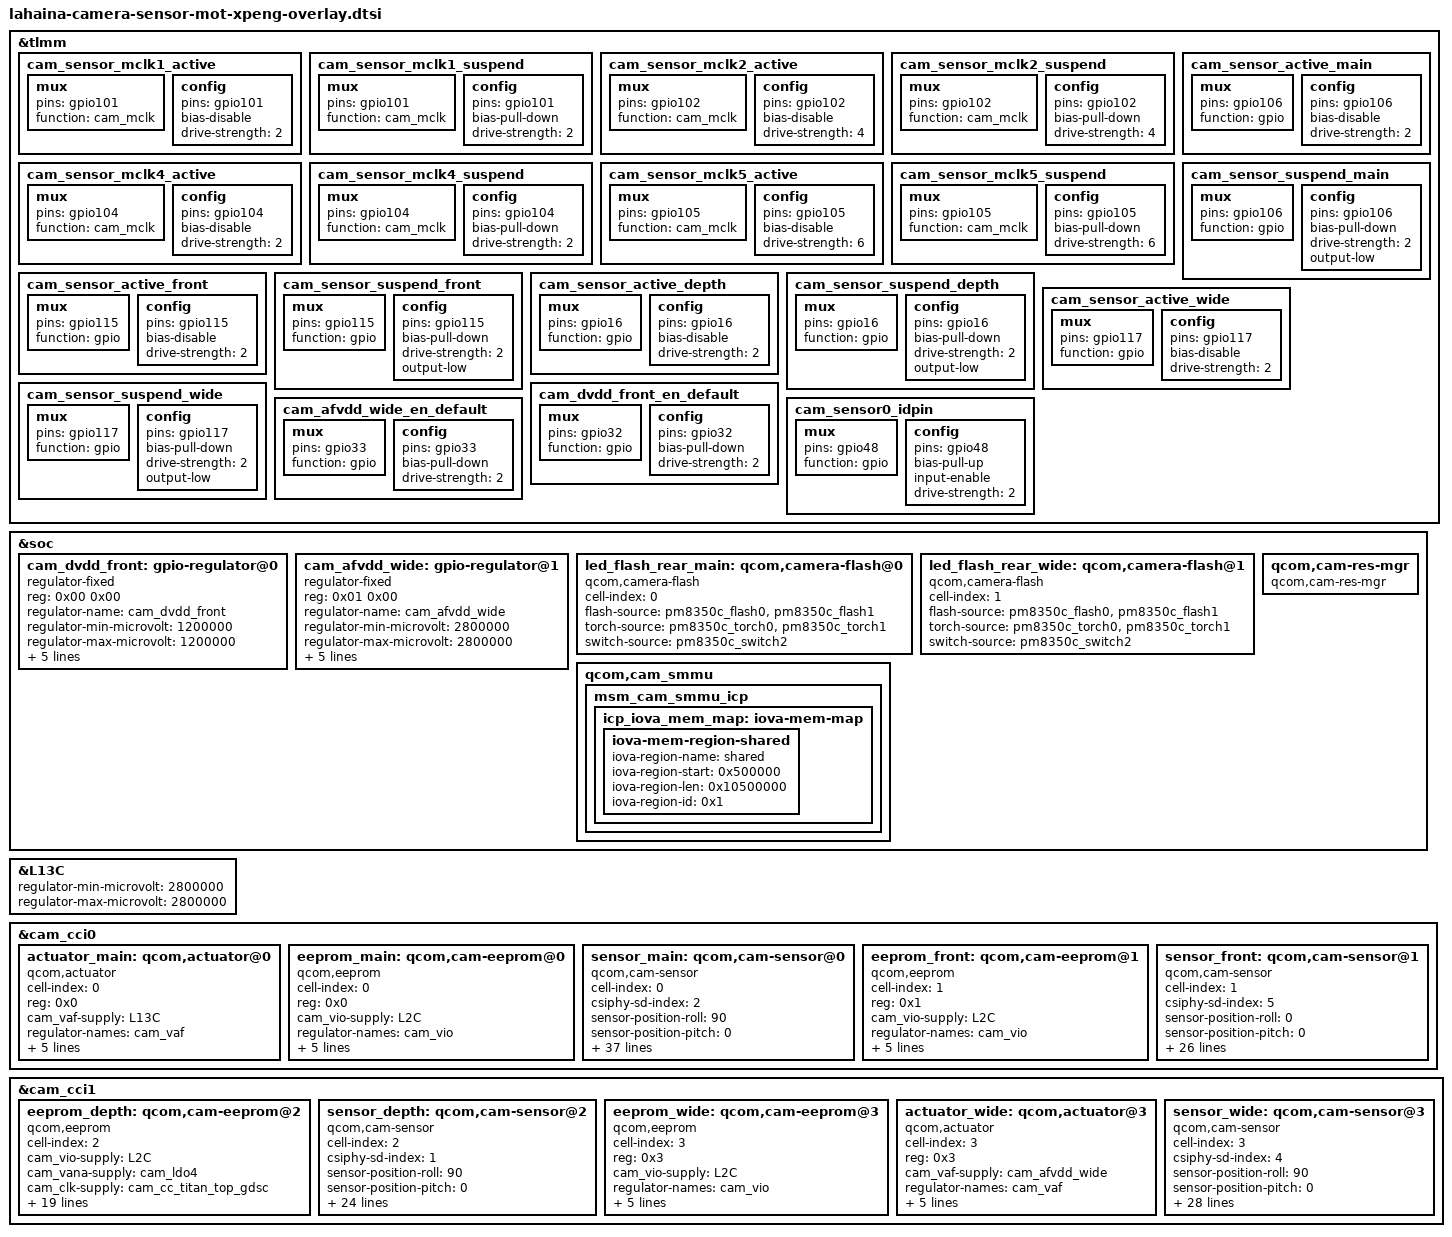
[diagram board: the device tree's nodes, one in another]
/* Copyright (c) 2020, The Linux Foundation. All rights reserved.
 *
 * This program is free software; you can redistribute it and/or modify
 * it under the terms of the GNU General Public License version 2 and
 * only version 2 as published by the Free Software Foundation.
 *
 * This program is distributed in the hope that it will be useful,
 * but WITHOUT ANY WARRANTY; without even the implied warranty of
 * MERCHANTABILITY or FITNESS FOR A PARTICULAR PURPOSE.  See the
 * GNU General Public License for more details.
 */

#include <dt-bindings/clock/qcom,camcc-lahaina.h>

&tlmm {
	cam_sensor_mclk1_active: cam_sensor_mclk1_active {
		mux {
			pins = "gpio101";
			function = "cam_mclk";
		};

		config {
			pins = "gpio101";
			bias-disable; /* No PULL */
			drive-strength = <2>; /* 2 MA */
		};
	};

	cam_sensor_mclk1_suspend: cam_sensor_mclk1_suspend {
		mux {
			pins = "gpio101";
			function = "cam_mclk";
		};

		config {
			pins = "gpio101";
			bias-pull-down; /* PULL DOWN */
			drive-strength = <2>; /* 2 MA */
		};
	};

	cam_sensor_mclk2_active: cam_sensor_mclk2_active {
		mux {
			pins = "gpio102";
			function = "cam_mclk";
		};

		config {
			pins = "gpio102";
			bias-disable; /* No PULL */
			drive-strength = <4>; /* 4 MA */
		};
	};

	cam_sensor_mclk2_suspend: cam_sensor_mclk2_suspend {
		mux {
			pins = "gpio102";
			function = "cam_mclk";
		};

		config {
			pins = "gpio102";
			bias-pull-down; /* PULL DOWN */
			drive-strength = <4>; /* 4 MA */
		};
	};

	cam_sensor_mclk4_active: cam_sensor_mclk4_active {
		mux {
			pins = "gpio104";
			function = "cam_mclk";
		};

		config {
			pins = "gpio104";
			bias-disable; /* No PULL */
			drive-strength = <2>; /* 2 MA */
		};
	};

	cam_sensor_mclk4_suspend: cam_sensor_mclk4_suspend {
		mux {
			pins = "gpio104";
			function = "cam_mclk";
		};

		config {
			pins = "gpio104";
			bias-pull-down; /* PULL DOWN */
			drive-strength = <2>; /* 2 MA */
		};
	};

	cam_sensor_mclk5_active: cam_sensor_mclk5_active {
		mux {
			pins = "gpio105";
			function = "cam_mclk";
		};

		config {
			pins = "gpio105";
			bias-disable; /* No PULL */
			drive-strength = <6>; /* 6 MA */
		};
	};

	cam_sensor_mclk5_suspend: cam_sensor_mclk5_suspend {
		mux {
			pins = "gpio105";
			function = "cam_mclk";
		};

		config {
			pins = "gpio105";
			bias-pull-down; /* PULL DOWN */
			drive-strength = <6>; /* 6 MA */
		};
	};

	cam_sensor_active_main: cam_sensor_active_main {
		mux {
			pins = "gpio106";
			function = "gpio";
		};

		config {
			pins = "gpio106";
			bias-disable; /* No PULL */
			drive-strength = <2>; /* 2 MA */
		};
	};

	cam_sensor_suspend_main: cam_sensor_suspend_main {
		mux {
			pins = "gpio106";
			function = "gpio";
		};

		config {
			pins = "gpio106";
			bias-pull-down; /* PULL DOWN */
			drive-strength = <2>; /* 2 MA */
			output-low;
		};
	};

	cam_sensor_active_front: cam_sensor_active_front {
		mux {
			pins = "gpio115";
			function = "gpio";
		};

		config {
			pins = "gpio115";
			bias-disable; /* No PULL */
			drive-strength = <2>; /* 2 MA */
		};
	};

	cam_sensor_suspend_front: cam_sensor_suspend_front {
		mux {
			pins = "gpio115";
			function = "gpio";
		};

		config {
			pins = "gpio115";
			bias-pull-down; /* PULL DOWN */
			drive-strength = <2>; /* 2 MA */
			output-low;
		};
	};

	cam_sensor_active_depth: cam_sensor_active_depth {
		mux {
			pins = "gpio16";
			function = "gpio";
		};

		config {
			pins = "gpio16";
			bias-disable; /* No PULL */
			drive-strength = <2>; /* 2 MA */
		};
	};

	cam_sensor_suspend_depth: cam_sensor_suspend_depth {
		mux {
			pins = "gpio16";
			function = "gpio";
		};

		config {
			pins = "gpio16";
			bias-pull-down; /* PULL DOWN */
			drive-strength = <2>; /* 2 MA */
			output-low;
		};
	};
	cam_sensor_active_wide: cam_sensor_active_wide {
		mux {
			pins = "gpio117";
			function = "gpio";
		};

		config {
			pins = "gpio117";
			bias-disable; /* No PULL */
			drive-strength = <2>; /* 2 MA */
		};
	};

	cam_sensor_suspend_wide: cam_sensor_suspend_wide {
		mux {
			pins = "gpio117";
			function = "gpio";
		};

		config {
			pins = "gpio117";
			bias-pull-down; /* PULL DOWN */
			drive-strength = <2>; /* 2 MA */
			output-low;
		};
	};

	cam_dvdd_front_en_default: cam_dvdd_front_en_default {
		mux {
			pins = "gpio32";
			function = "gpio";
		};

		config {
			pins = "gpio32";
			bias-pull-down; /* PULL DOWN */
			drive-strength = <2>; /* 2 MA */
		};
	};

	cam_afvdd_wide_en_default: cam_afvdd_wide_en_default {
		mux {
			pins = "gpio33";
			function = "gpio";
		};

		config {
			pins = "gpio33";
			bias-pull-down; /* PULL DOWN */
			drive-strength = <2>; /* 2 MA */
		};
	};

	cam_sensor0_idpin: cam_sensor0_idpin {
		/* ID PIN */
		mux {
			pins = "gpio48";
			function = "gpio";
		};

		config {
			pins = "gpio48";
			bias-pull-up; /* PULL UP */
			input-enable;
			drive-strength = <2>; /* 2 MA */
		};
	};
};

&soc {
	cam_dvdd_front: gpio-regulator@0 {
		compatible = "regulator-fixed";
		reg = <0x00 0x00>;
		regulator-name = "cam_dvdd_front";
		regulator-min-microvolt = <1200000>;
		regulator-max-microvolt = <1200000>;
		regulator-enable-ramp-delay = <233>;
		enable-active-high;
		gpio = <&tlmm 32 0>;
		pinctrl-names = "default";
		pinctrl-0 = <&cam_dvdd_front_en_default>;
		vin-supply = <&S12B>;
	};

	cam_afvdd_wide: gpio-regulator@1 {
		compatible = "regulator-fixed";
		reg = <0x01 0x00>;
		regulator-name = "cam_afvdd_wide";
		regulator-min-microvolt = <2800000>;
		regulator-max-microvolt = <2800000>;
		regulator-enable-ramp-delay = <233>;
		enable-active-high;
		gpio = <&tlmm 33 0>;
		pinctrl-names = "default";
		pinctrl-0 = <&cam_afvdd_wide_en_default>;
		vin-supply = <&BOB>;
	};

	led_flash_rear_main: qcom,camera-flash@0 {
		cell-index = <0>;
		compatible = "qcom,camera-flash";
		flash-source = <&pm8350c_flash0 &pm8350c_flash1>;
		torch-source = <&pm8350c_torch0 &pm8350c_torch1>;
		switch-source = <&pm8350c_switch2>;
		status = "ok";
	};

	led_flash_rear_wide: qcom,camera-flash@1 {
		cell-index = <1>;
		compatible = "qcom,camera-flash";
		flash-source = <&pm8350c_flash0 &pm8350c_flash1>;
		torch-source = <&pm8350c_torch0 &pm8350c_torch1>;
		switch-source = <&pm8350c_switch2>;
		status = "ok";
	};

	qcom,cam-res-mgr {
		compatible = "qcom,cam-res-mgr";
		status = "ok";
	};

	qcom,cam_smmu {
		msm_cam_smmu_icp {
			icp_iova_mem_map: iova-mem-map {
				iova-mem-region-shared {
					/* Shared region is 261MB long */
					iova-region-name = "shared";
					iova-region-start = <0x500000>;
					iova-region-len = <0x10500000>;
					iova-region-id = <0x1>;
					status = "ok";
				};
			};
		};
	};
};

&L13C {
    regulator-min-microvolt = <2800000>;
    regulator-max-microvolt = <2800000>;
};

&cam_cci0 {
	actuator_main: qcom,actuator@0 {
		cell-index = <0>;
		reg = <0x0>;
		compatible = "qcom,actuator";
		cam_vaf-supply = <&L13C>;
		regulator-names = "cam_vaf";
		rgltr-cntrl-support;
		rgltr-min-voltage = <2800000>;
		rgltr-max-voltage = <2800000>;
		rgltr-load-current = <105000>;
		cci-master = <0>;
		status = "ok";
	};

	eeprom_main: qcom,cam-eeprom@0 {
		cell-index = <0>;
		reg = <0x0>;
		compatible = "qcom,eeprom";
		cam_vio-supply = <&L2C>;
		regulator-names = "cam_vio";
		rgltr-cntrl-support;
		rgltr-min-voltage = <1800000>;
		rgltr-max-voltage = <1800000>;
		rgltr-load-current = <3000>;
		cci-master = <0>;
		status = "ok";
    };

	sensor_main: qcom,cam-sensor@0 {
		cell-index = <0>;
		compatible = "qcom,cam-sensor";
		csiphy-sd-index = <2>;
		sensor-position-roll = <90>;
		sensor-position-pitch = <0>;
		sensor-position-yaw = <180>;
		actuator-src = <&actuator_main>;
		eeprom-src = <&eeprom_main>;
		led-flash-src = <&led_flash_rear_main>;
		cam_vio-supply = <&L2C>;
		cam_vana-supply = <&cam_ldo3>;
		cam_vdig-supply = <&cam_ldo1>;
		cam_vaf-supply = <&L13C>;
		cam_clk-supply = <&cam_cc_titan_top_gdsc>;
		regulator-names = "cam_vio", "cam_vana",
			"cam_vdig","cam_vaf","cam_clk";
		rgltr-cntrl-support;
		rgltr-min-voltage = <1800000 2800000 1104000 2800000 0>;
		rgltr-max-voltage = <1800000 2800000 1104000 2800000 0>;
		rgltr-load-current = <3000 132000 405000 100000 0>;
		gpio-no-mux = <0>;
		pinctrl-names = "cam_default", "cam_suspend","default";
		pinctrl-0 = <&cam_sensor_mclk2_active
				&cam_sensor_active_main>;
		pinctrl-1 = <&cam_sensor_mclk2_suspend
				&cam_sensor_suspend_main>;
		pinctrl-2 = <&cam_sensor0_idpin>;
		gpios = <&tlmm 102 0>,
			<&tlmm 106 0>;
		gpio-reset = <1>;
		gpio-req-tbl-num = <0 1>;
		gpio-req-tbl-flags = <1 0>;
		gpio-req-tbl-label = "CAMIF_MCLK2",
					"CAM_RESET2";
		cci-master = <0>;
		status = "ok";
		clocks = <&clock_camcc CAM_CC_MCLK2_CLK>;
		clock-names = "cam_clk";
		clock-cntl-level = "nominal";
		clock-rates = <24000000>;
		/* gpio for distinguish different camera sensor */
		volt-compat-gpio = <&tlmm 48 0x0>;
		volt-compat-gpio-value = <0>;
		volt-compat-rgltr-name = "cam_vdig";
		/* second rear camera sensor voltage */
		volt-compat-range = <1050000 1050000>;
	};

	eeprom_front: qcom,cam-eeprom@1 {
		cell-index = <1>;
		reg = <0x1>;
		compatible = "qcom,eeprom";
		cam_vio-supply = <&L2C>;
		regulator-names = "cam_vio";
		rgltr-cntrl-support;
		rgltr-min-voltage = <1800000>;
		rgltr-max-voltage = <1800000>;
		rgltr-load-current = <3000>;
		cci-master = <1>;
		status = "ok";
    };

	sensor_front: qcom,cam-sensor@1 {
		cell-index = <1>;
		compatible = "qcom,cam-sensor";
		csiphy-sd-index = <5>;
		sensor-position-roll = <0>;
		sensor-position-pitch = <0>;
		sensor-position-yaw = <0>;
		eeprom-src = <&eeprom_front>;
		cam_vio-supply = <&L2C>;
		cam_vana-supply = <&cam_ldo4>;
		cam_vdig-supply = <&cam_dvdd_front>;
		cam_clk-supply = <&cam_cc_titan_top_gdsc>;
		regulator-names = "cam_vio", "cam_vana",
			"cam_vdig","cam_clk";
		rgltr-cntrl-support;
		rgltr-min-voltage = <1800000 2800000 1200000 0>;
		rgltr-max-voltage = <1800000 2800000 1200000 0>;
		rgltr-load-current = <3000 132000 405000 0>;
		gpio-no-mux = <0>;
		pinctrl-names = "cam_default", "cam_suspend";
		pinctrl-0 = <&cam_sensor_mclk5_active
				&cam_sensor_active_main>;
		pinctrl-1 = <&cam_sensor_mclk5_suspend
				&cam_sensor_suspend_main>;
		gpios = <&tlmm 105 0>,
			<&tlmm 115 0>;
		gpio-reset = <1>;
		gpio-req-tbl-num = <0 1>;
		gpio-req-tbl-flags = <1 0>;
		gpio-req-tbl-label = "CAMIF_MCLK5",
					"CAM_RESET5";
		cci-master = <1>;
		status = "ok";
		clocks = <&clock_camcc CAM_CC_MCLK5_CLK>;
		clock-names = "cam_clk";
		clock-cntl-level = "nominal";
		clock-rates = <24000000>;
	};
};

&cam_cci1 {
	eeprom_depth: qcom,cam-eeprom@2 {
		cell-index = <2>;
		compatible = "qcom,eeprom";
		cam_vio-supply = <&L2C>;
		cam_vana-supply = <&cam_ldo4>;
		cam_clk-supply = <&cam_cc_titan_top_gdsc>;
		regulator-names = "cam_vio", "cam_vana","cam_clk";
		rgltr-cntrl-support;
		rgltr-min-voltage = <1800000 2800000 0>;
		rgltr-max-voltage = <1800000 2800000 0>;
		rgltr-load-current = <3000 28000 0>;
		gpio-no-mux = <0>;
		pinctrl-names = "cam_default", "cam_suspend";
		pinctrl-0 = <&cam_sensor_mclk1_active
				&cam_sensor_active_depth>;
		pinctrl-1 = <&cam_sensor_mclk1_suspend
				&cam_sensor_suspend_depth>;
		gpios = <&tlmm 101 0>,
			<&tlmm 16 0>;
		gpio-reset = <1>;
		gpio-req-tbl-num = <0 1>;
		gpio-req-tbl-flags = <1 0>;
		gpio-req-tbl-label = "CAMIF_MCLK1",
					"CAM_RESET1";
		cci-master = <1>;
		status = "ok";
		clocks = <&clock_camcc CAM_CC_MCLK1_CLK>;
		clock-names = "cam_clk";
		clock-cntl-level = "nominal";
		clock-rates = <24000000>;
    };

	sensor_depth: qcom,cam-sensor@2 {
		cell-index = <2>;
		compatible = "qcom,cam-sensor";
		csiphy-sd-index = <1>;
		sensor-position-roll = <90>;
		sensor-position-pitch = <0>;
		sensor-position-yaw = <180>;
		eeprom-src = <&eeprom_depth>;
		cam_vio-supply = <&L2C>;
		cam_vana-supply = <&cam_ldo4>;
		cam_clk-supply = <&cam_cc_titan_top_gdsc>;
		regulator-names = "cam_vio", "cam_vana","cam_clk";
		rgltr-cntrl-support;
		rgltr-min-voltage = <1800000 2800000 0>;
		rgltr-max-voltage = <1800000 2800000 0>;
		rgltr-load-current = <3000 28000 0>;
		gpio-no-mux = <0>;
		pinctrl-names = "cam_default", "cam_suspend";
		pinctrl-0 = <&cam_sensor_mclk1_active
				&cam_sensor_active_depth>;
		pinctrl-1 = <&cam_sensor_mclk1_suspend
				&cam_sensor_suspend_depth>;
		gpios = <&tlmm 101 0>,
			<&tlmm 16 0>;
		gpio-reset = <1>;
		gpio-req-tbl-num = <0 1>;
		gpio-req-tbl-flags = <1 0>;
		gpio-req-tbl-label = "CAMIF_MCLK1",
					"CAM_RESET1";
		cci-master = <1>;
		status = "ok";
		clocks = <&clock_camcc CAM_CC_MCLK1_CLK>;
		clock-names = "cam_clk";
		clock-cntl-level = "nominal";
		clock-rates = <24000000>;
	};

	eeprom_wide: qcom,cam-eeprom@3 {
		cell-index = <3>;
		reg = <0x3>;
		compatible = "qcom,eeprom";
		cam_vio-supply = <&L2C>;
		regulator-names = "cam_vio";
		rgltr-cntrl-support;
		rgltr-min-voltage = <1800000>;
		rgltr-max-voltage = <1800000>;
		rgltr-load-current = <3000>;
		cci-master = <0>;
		status = "ok";
    };

	actuator_wide: qcom,actuator@3 {
		cell-index = <3>;
		reg = <0x3>;
		compatible = "qcom,actuator";
		cam_vaf-supply = <&cam_afvdd_wide>;
		regulator-names = "cam_vaf";
		rgltr-cntrl-support;
		rgltr-min-voltage = <2800000>;
		rgltr-max-voltage = <2800000>;
		rgltr-load-current = <105000>;
		cci-master = <0>;
		status = "ok";
	};

	sensor_wide: qcom,cam-sensor@3 {
		cell-index = <3>;
		compatible = "qcom,cam-sensor";
		csiphy-sd-index = <4>;
		sensor-position-roll = <90>;
		sensor-position-pitch = <0>;
		sensor-position-yaw = <180>;
		eeprom-src = <&eeprom_wide>;
		actuator-src = <&actuator_wide>;
		led-flash-src = <&led_flash_rear_wide>;
		cam_vio-supply = <&L2C>;
		cam_vana-supply = <&cam_ldo4>;
		cam_vdig-supply = <&cam_ldo2>;
		cam_clk-supply = <&cam_cc_titan_top_gdsc>;
		regulator-names = "cam_vio", "cam_vana", "cam_vdig",
			"cam_clk";
		rgltr-cntrl-support;
		rgltr-min-voltage = <1800000 2800000 1104000 0>;
		rgltr-max-voltage = <1800000 2800000 1104000 0>;
		rgltr-load-current = <3000 132000 405000 0>;
		gpio-no-mux = <0>;
		pinctrl-names = "cam_default", "cam_suspend";
		pinctrl-0 = <&cam_sensor_mclk4_active
				&cam_sensor_active_wide>;
		pinctrl-1 = <&cam_sensor_mclk4_suspend
				&cam_sensor_suspend_wide>;
		gpios = <&tlmm 104 0>,
			<&tlmm 117 0>;
		gpio-reset = <1>;
		gpio-req-tbl-num = <0 1>;
		gpio-req-tbl-flags = <1 0>;
		gpio-req-tbl-label = "CAMIF_MCLK4",
					"CAM_RESET4";
		cci-master = <0>;
		status = "ok";
		clocks = <&clock_camcc CAM_CC_MCLK4_CLK>;
		clock-names = "cam_clk";
		clock-cntl-level = "nominal";
		clock-rates = <24000000>;
	};
};
